# COMPUTE_CLUSTER_J7AHP0_DRU_0_MMR_DRU7_MMR_CFG_DRU_MMU register map
Vendor: Texas Instruments
Peripheral module from a debugger description file (folder J7_AHP).
Registers are 64-bit, access per field, reset values left out (the file's numbers can be read two ways) unless marked. A register's access mark holds for its fields unless they carry their own. Offsets are as the file gives them; lines under a group give offsets from that group; [hi:lo] are bit positions; {n}, {i} and the like mark numbered series; 'fields as' and 'values as' point back to an identical list; <NAME> marks a mode.

## COMPUTE_CLUSTER_J7AHP0_DRU_0_MMR_DRU7_MMR_CFG_DRU_MMU
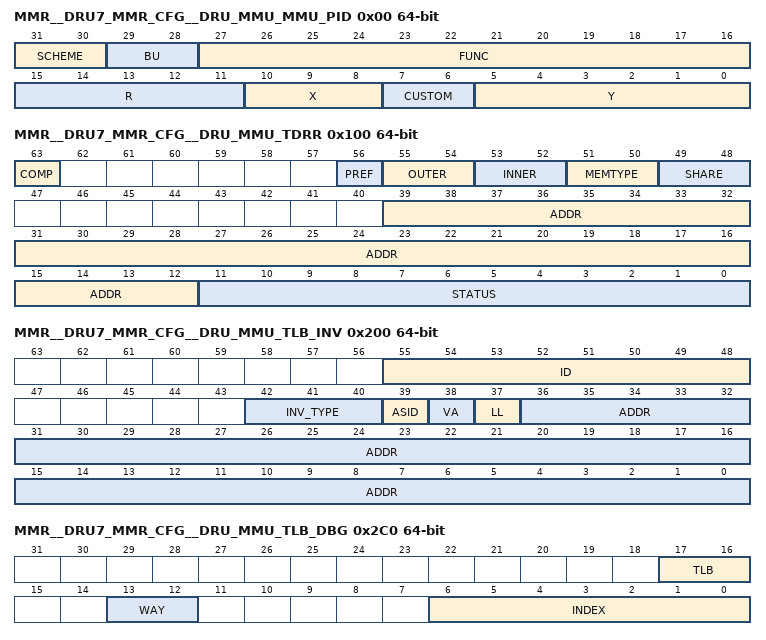
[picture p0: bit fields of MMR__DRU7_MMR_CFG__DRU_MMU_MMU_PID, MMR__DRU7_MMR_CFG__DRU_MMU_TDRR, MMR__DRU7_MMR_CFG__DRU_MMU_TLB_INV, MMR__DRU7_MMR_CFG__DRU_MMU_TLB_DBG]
0x00 MMR__DRU7_MMR_CFG__DRU_MMU_MMU_PID ro
  [31:30] SCHEME — PID naming scheme
  [29:28] BU — Business Unit
  [27:16] FUNC — MMU Function code
  [15:11] R — Minor Revision
  [10:8] X — Architecture Revision
  [7:6] CUSTOM — Reuseable/Custom
  [5:0] Y — Configuration Revision
0x100 MMR__DRU7_MMR_CFG__DRU_MMU_TDRR
  [63] COMP rw — Translation Completion Bit
  [56] PREF rw — Prefetchable
  [55:54] OUTER rw — Outer Cacheability
  [53:52] INNER rw — Inner Cacheability
  [51:50] MEMTYPE rw — Memory Type
  [49:48] SHARE rw — Shareability
  [39:12] ADDR rw — Output Address, Faulting Stage-2 IPA
  [11:0] STATUS rw — Translation Response Status
0x140 MMR__DRU7_MMR_CFG__DRU_MMU_TDFAR rw
  [63:0] ADDR — Faulted Input Address
0x200 MMR__DRU7_MMR_CFG__DRU_MMU_TLB_INV
  [55:48] ID wo — ASID Value
  [42:40] INV_TYPE wo — Invalidation Type
  [39] ASID wo — ASID Match
  [38] VA wo — VA Match
  [37] LL wo — Last Level Only
  [36:0] ADDR wo — VA/IPA
0x280 MMR__DRU7_MMR_CFG__DRU_MMU_TLB_INVC
  [0] COMP rw — Invalidation Completed
0x2C0 MMR__DRU7_MMR_CFG__DRU_MMU_TLB_DBG
  [17:16] TLB wo — TLB Type
  [13:12] WAY wo
  [6:0] INDEX wo
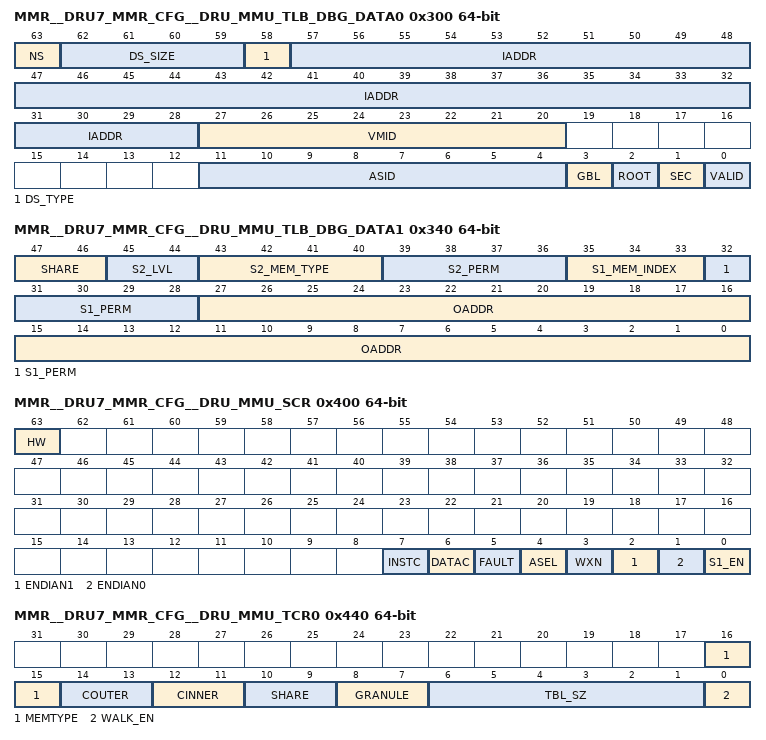
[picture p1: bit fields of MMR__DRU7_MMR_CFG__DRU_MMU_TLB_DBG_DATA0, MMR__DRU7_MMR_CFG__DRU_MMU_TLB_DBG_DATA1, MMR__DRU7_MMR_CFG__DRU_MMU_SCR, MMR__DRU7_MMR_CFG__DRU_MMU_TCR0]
0x300 MMR__DRU7_MMR_CFG__DRU_MMU_TLB_DBG_DATA0 ro
  [63] NS — Non-Secure Page, NSTable accumulation
  [62:59] DS_SIZE — Descriptor Size
  [58] DS_TYPE — Descriptor Type
  [57:28] IADDR — Input Address
  [27:20] VMID
  [11:4] ASID
  [3] GBL — Global Page
  [2] ROOT — Root Context
  [1] SEC — Security Context
  [0] VALID — Valid Entry
0x340 MMR__DRU7_MMR_CFG__DRU_MMU_TLB_DBG_DATA1 ro
  [47:46] SHARE — Shareability
  [45:44] S2_LVL — Stage 2 Level
  [43:40] S2_MEM_TYPE — Stage 2 Memory Type
  [39:36] S2_PERM — S2 Access Permissions
  [35:33] S1_MEM_INDEX — Stage 1 Memory Attribute Index
  [32:28] S1_PERM — Stage 1 Access Permissions
  [27:0] OADDR — Output Address
0x400 MMR__DRU7_MMR_CFG__DRU_MMU_SCR
  [63] HW rw — HW Mode
  [7] INSTC rw — Stage 1 Instruction Caching
  [6] DATAC rw — Stage 1 Data Caching
  [5] FAULT rw — Caching faults in uTLBs
  [4] ASEL rw — ASID Selection
  [3] WXN rw — Writeable memory Execute Never
  [2] ENDIAN1 rw — Stage 1 Region 1 Endian
  [1] ENDIAN0 rw — Stage 1 Region 0 Endian
  [0] S1_EN rw — Enable Stage 1 Address Translation
0x440 MMR__DRU7_MMR_CFG__DRU_MMU_TCR0
  [16:15] MEMTYPE rw — Memory Type of Translation Table Walks
  [14:13] COUTER rw — Outer Cacheability attribute of memory for Translation Table Walks
  [12:11] CINNER rw — Inner Cacheability attribute of memory for Translation Table Walks
  [10:9] SHARE rw — Shareability attribute of memory for Translation Table Walks
  [8:7] GRANULE rw — Translation Table Page Granule Size
  [6:1] TBL_SZ rw — Translation Table Region Size
  [0] WALK_EN rw — Enable Translation Table Walks
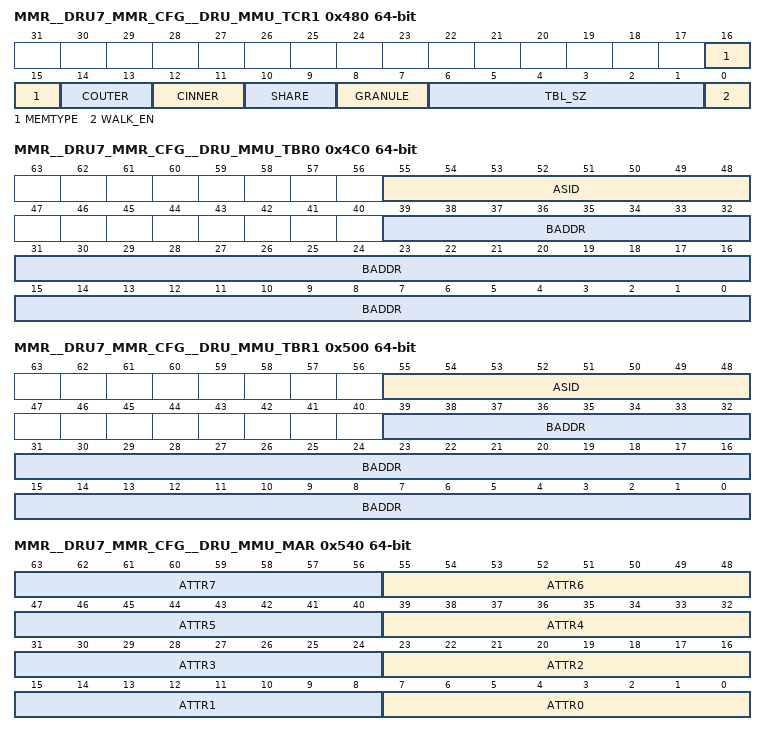
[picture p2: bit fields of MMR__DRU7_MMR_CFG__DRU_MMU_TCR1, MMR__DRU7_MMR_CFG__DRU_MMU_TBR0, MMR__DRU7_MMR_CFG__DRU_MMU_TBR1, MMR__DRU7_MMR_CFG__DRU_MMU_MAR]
0x480 MMR__DRU7_MMR_CFG__DRU_MMU_TCR1
  fields as MMR__DRU7_MMR_CFG__DRU_MMU_TCR0
0x4C0 MMR__DRU7_MMR_CFG__DRU_MMU_TBR0
  [55:48] ASID rw — Application Space ID
  [39:0] BADDR rw — Table Base Address
0x500 MMR__DRU7_MMR_CFG__DRU_MMU_TBR1
  fields as MMR__DRU7_MMR_CFG__DRU_MMU_TBR0
0x540 MMR__DRU7_MMR_CFG__DRU_MMU_MAR rw
  [8n+7:8n] ATTR{n} (n=0..7) — Memory Attribute Index {n}
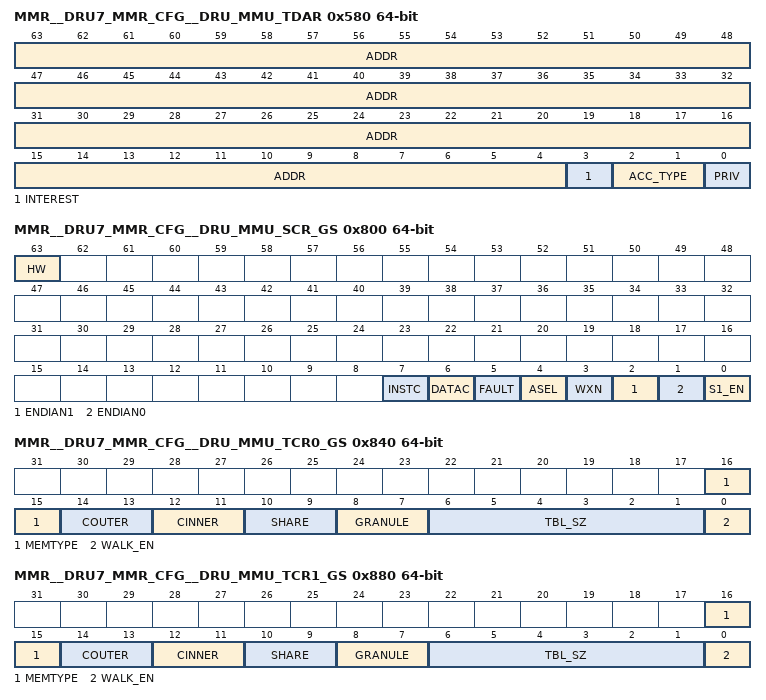
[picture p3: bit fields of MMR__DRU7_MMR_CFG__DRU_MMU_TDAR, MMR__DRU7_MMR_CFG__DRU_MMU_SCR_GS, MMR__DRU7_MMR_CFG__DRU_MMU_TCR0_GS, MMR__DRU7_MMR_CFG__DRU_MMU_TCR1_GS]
0x580 MMR__DRU7_MMR_CFG__DRU_MMU_TDAR wo
  [63:4] ADDR — Input Address
  [3] INTEREST — Interest Flag
  [2:1] ACC_TYPE — Access Type
  [0] PRIV — Supervisor Access
0x800 MMR__DRU7_MMR_CFG__DRU_MMU_SCR_GS
  fields as MMR__DRU7_MMR_CFG__DRU_MMU_SCR
0x840 MMR__DRU7_MMR_CFG__DRU_MMU_TCR0_GS
  fields as MMR__DRU7_MMR_CFG__DRU_MMU_TCR0
0x880 MMR__DRU7_MMR_CFG__DRU_MMU_TCR1_GS
  fields as MMR__DRU7_MMR_CFG__DRU_MMU_TCR0
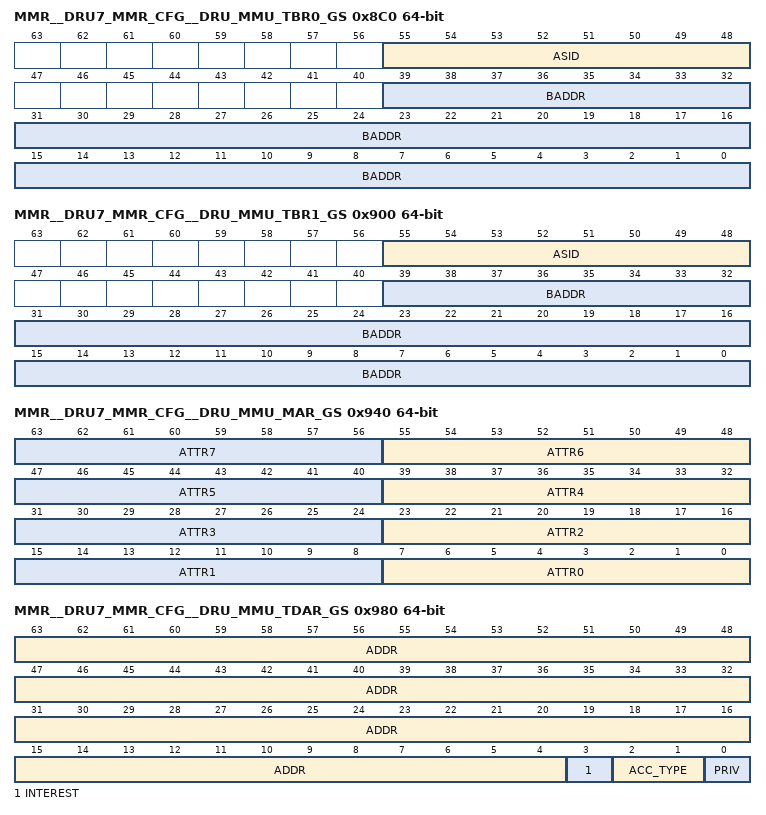
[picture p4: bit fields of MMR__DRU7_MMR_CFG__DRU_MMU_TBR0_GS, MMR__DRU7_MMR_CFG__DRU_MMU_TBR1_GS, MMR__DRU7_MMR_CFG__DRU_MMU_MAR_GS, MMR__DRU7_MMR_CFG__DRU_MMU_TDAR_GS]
0x8C0 MMR__DRU7_MMR_CFG__DRU_MMU_TBR0_GS
  fields as MMR__DRU7_MMR_CFG__DRU_MMU_TBR0
0x900 MMR__DRU7_MMR_CFG__DRU_MMU_TBR1_GS
  fields as MMR__DRU7_MMR_CFG__DRU_MMU_TBR0
0x940 MMR__DRU7_MMR_CFG__DRU_MMU_MAR_GS rw
  [8n+7:8n] ATTR{n} (n=0..7) — Memory Attribute Index {n}
0x980 MMR__DRU7_MMR_CFG__DRU_MMU_TDAR_GS wo
  fields as MMR__DRU7_MMR_CFG__DRU_MMU_TDAR
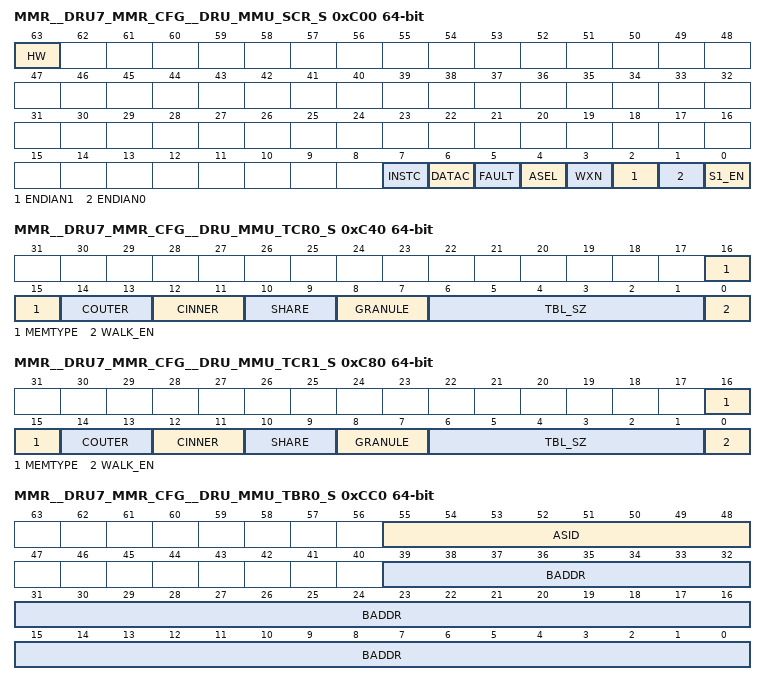
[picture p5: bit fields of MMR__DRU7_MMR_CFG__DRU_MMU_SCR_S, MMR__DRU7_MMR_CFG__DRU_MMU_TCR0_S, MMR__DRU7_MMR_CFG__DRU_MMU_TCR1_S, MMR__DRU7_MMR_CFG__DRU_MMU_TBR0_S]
0xC00 MMR__DRU7_MMR_CFG__DRU_MMU_SCR_S
  fields as MMR__DRU7_MMR_CFG__DRU_MMU_SCR
0xC40 MMR__DRU7_MMR_CFG__DRU_MMU_TCR0_S
  fields as MMR__DRU7_MMR_CFG__DRU_MMU_TCR0
0xC80 MMR__DRU7_MMR_CFG__DRU_MMU_TCR1_S
  fields as MMR__DRU7_MMR_CFG__DRU_MMU_TCR0
0xCC0 MMR__DRU7_MMR_CFG__DRU_MMU_TBR0_S
  fields as MMR__DRU7_MMR_CFG__DRU_MMU_TBR0
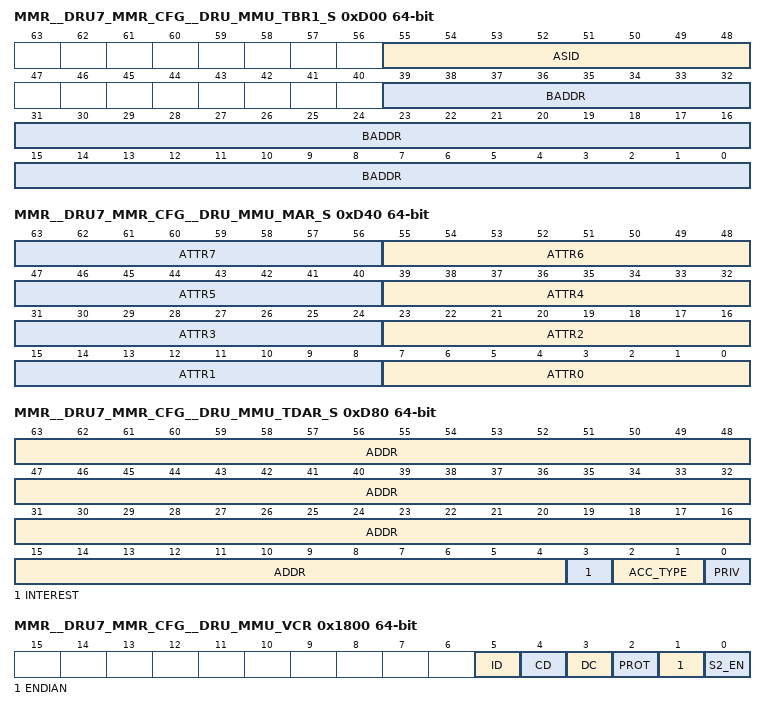
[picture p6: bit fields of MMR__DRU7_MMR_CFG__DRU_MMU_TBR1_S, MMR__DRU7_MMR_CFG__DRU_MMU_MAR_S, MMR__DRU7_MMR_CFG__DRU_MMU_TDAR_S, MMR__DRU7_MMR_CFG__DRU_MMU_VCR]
0xD00 MMR__DRU7_MMR_CFG__DRU_MMU_TBR1_S
  fields as MMR__DRU7_MMR_CFG__DRU_MMU_TBR0
0xD40 MMR__DRU7_MMR_CFG__DRU_MMU_MAR_S rw
  [8n+7:8n] ATTR{n} (n=0..7) — Memory Attribute Index {n}
0xD80 MMR__DRU7_MMR_CFG__DRU_MMU_TDAR_S wo
  fields as MMR__DRU7_MMR_CFG__DRU_MMU_TDAR
0x1800 MMR__DRU7_MMR_CFG__DRU_MMU_VCR
  [5] ID rw — Stage 2 Instruction Cache Disable
  [4] CD rw — Stage 2 Data Cache Disable
  [3] DC rw — Default Cacheable Mode
  [2] PROT rw — Protected Table Walk
  [1] ENDIAN rw — Stage 2 Endian
  [0] S2_EN rw — Enable Stage 2 Address Translation
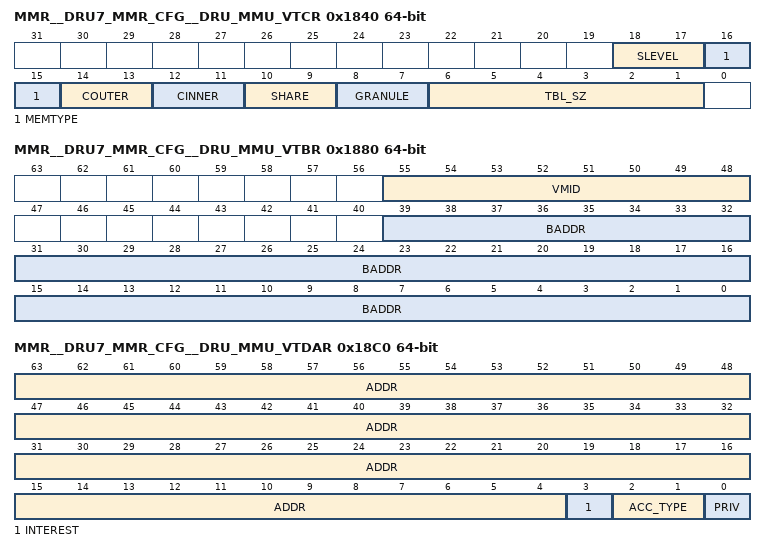
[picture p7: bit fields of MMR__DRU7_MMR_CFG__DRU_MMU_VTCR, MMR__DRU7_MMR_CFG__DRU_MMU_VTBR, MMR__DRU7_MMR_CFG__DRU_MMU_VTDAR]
0x1840 MMR__DRU7_MMR_CFG__DRU_MMU_VTCR
  [18:17] SLEVEL rw — Stage 2 Starting Translation Level
  [16:15] MEMTYPE rw — Memory Type of Translation Table Walks
  [14:13] COUTER rw — Outer Cacheability attribute of memory for Translation Table Walks
  [12:11] CINNER rw — Inner Cacheability attribute of memory for Translation Table Walks
  [10:9] SHARE rw — Shareability attribute of memory for Translation Table Walks
  [8:7] GRANULE rw — Translation Table Page Granule Size
  [6:1] TBL_SZ rw — Translation Table Region Size
0x1880 MMR__DRU7_MMR_CFG__DRU_MMU_VTBR
  [55:48] VMID rw — Virtual Machine ID
  [39:0] BADDR rw — Table Base Address
0x18C0 MMR__DRU7_MMR_CFG__DRU_MMU_VTDAR wo
  fields as MMR__DRU7_MMR_CFG__DRU_MMU_TDAR
